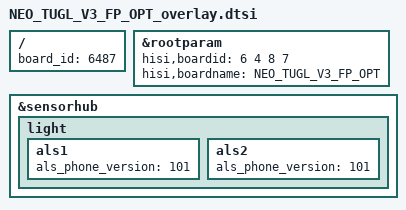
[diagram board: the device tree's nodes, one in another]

/**
 * Copyright (C) 2014 Hisilicon Ltd.
 *
 *  This program is free software; you can redistribute it and/or modify
 *  it under the terms of the GNU General Public License version 2 as
 *  publishhed by the Free Software Foundation.
 */

/include/ "NEO_TUGL_V2_FP_OPT_overlay.dtsi"

/ {
        board_id = <6487>;
};

&rootparam {
    hisi,boardid = <6 4 8 7>;
    hisi,boardname = "NEO_TUGL_V3_FP_OPT";
};


&sensorhub{
                light{
                        als1{
                               als_phone_version = <101>;
                        };
                        als2{
                               als_phone_version = <101>;
                        };
                };
        };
